VERSION "All_Common"

NS_ :

BS_:

BU_: IPC PCM VSA ADAS UNKNOWN

BO_ 422 IPC_0x1A6: 8 IPC
 SG_ HEADLIGHT_STATE : 0|2@1+ (1,0) [0|3] ""  PCM
 SG_ LIGHTING_STATUS_TBD : 2|1@1+ (1,0) [0|1] ""  PCM
 SG_ BRAKE_FLUID_LEVEL : 3|1@1+ (1,0) [0|1] ""  PCM
 SG_ PARKBRAKE_CURRENT : 4|1@1+ (1,0) [0|1] ""  PCM
 SG_ CRUISE_CONTROL_SYSTEM_SWITCH_STATUS : 5|3@1+ (1,0) [0|7] ""  PCM
 SG_ UNKNOWN_1 : 8|2@1+ (1,0) [0|3] ""  PCM
 SG_ SELECTED_BODY_STATUS_0 : 10|1@1+ (1,0) [0|1] ""  PCM
 SG_ SELECTED_BODY_STATUS_1 : 11|1@1+ (1,0) [0|1] ""  PCM
 SG_ BODY_STATUS : 12|2@1+ (1,0) [0|3] ""  PCM
 SG_ UNKNOWN_2 : 14|2@1+ (1,0) [0|3] ""  PCM
 SG_ FCAN_30C_STATUS_6 : 16|1@1+ (1,0) [0|1] ""  PCM
 SG_ FCAN_30C_STATUS_7 : 17|1@1+ (1,0) [0|1] ""  PCM
 SG_ BACKUP_LIGHT_SWITCH_REF : 18|1@1+ (1,0) [0|1] ""  PCM
 SG_ STATUS_BIT_1 : 19|1@1+ (1,0) [0|1] ""  PCM
 SG_ AC_COMPRESSOR_ON : 20|1@1+ (1,0) [0|1] ""  PCM
 SG_ STATUS_BIT_2 : 21|1@1+ (1,0) [0|1] ""  PCM
 SG_ STATUS_BIT_1_TBD : 22|1@1+ (1,0) [0|1] ""  PCM
 SG_ MONITOR_STATUS : 23|1@1+ (1,0) [0|1] ""  PCM
 SG_ FUEL_LEVEL_SCALED : 24|8@1+ (1,0) [0|255] ""  PCM
 SG_ FUEL_LEVEL_SENSOR_VOLTAGE : 32|8@1+ (0.01953130029153824,0) [0|4.980481574342251] "V"  PCM
 SG_ STATUS_BIT_3 : 40|1@1+ (1,0) [0|1] ""  PCM
 SG_ STATUS_BIT_4 : 41|1@1+ (1,0) [0|1] ""  PCM
 SG_ ACC_LKAS_SWITCH_STATUS_REF : 42|3@1+ (1,0) [0|7] ""  PCM
 SG_ UNKNOWN_3 : 45|2@1+ (1,0) [0|3] ""  PCM
 SG_ CRUISE_MAIN_SWITCH_HIDS_IHCC_ACC_INDICATOR : 47|1@1+ (1,0) [0|1] ""  PCM
 SG_ UNKNOWN_4 : 48|5@1+ (1,0) [0|31] ""  PCM
 SG_ FCAN_1FA_RECEIVE_FAULT : 53|1@1+ (1,0) [0|1] ""  PCM
 SG_ FCAN_RECEIVE_FAULT_A : 54|1@1+ (1,0) [0|1] ""  PCM
 SG_ FCAN_RECEIVE_FAULT_B : 55|1@1+ (1,0) [0|1] ""  PCM
 SG_ CHECKSUM : 56|4@1+ (1,0) [0|15] ""  PCM
 SG_ COUNTER : 60|2@1+ (1,0) [0|3] ""  PCM
 SG_ BCAN_SUPERVISION : 62|1@1+ (1,0) [0|1] ""  PCM
 SG_ STATUS_BIT_2_TBD : 63|1@1+ (1,0) [0|1] ""  PCM
VAL_ 422 CRUISE_CONTROL_SYSTEM_SWITCH_STATUS 0 "DEFAULT" 1 "MAIN_SWITCH" 2 "CANCEL_SWITCH" 3 "SET_SWITCH" 4 "RESUME_SWITCH" 5 "UNKNOWN" 6 "SIGNAL_LOST" 7 "SIGNAL_SHORT" ;
VAL_ 422 BRAKE_FLUID_LEVEL 0 "ENOUGH" 1 "LOW" ;
VAL_ 422 HEADLIGHT_STATE 0 "OFF_OR_UNAVAILABLE" 1 "PARKING_LIGHTS" 2 "LOW_BEAM" 3 "HIGH_BEAM" ;
VAL_ 422 ACC_LKAS_SWITCH_STATUS_REF 0 "NO_SWITCH_REQUEST" 1 "LKAS_SWITCH" 3 "DISTANCE_SWITCH" 6 "SWITCH_CIRCUIT_OPEN" 7 "SWITCH_CIRCUIT_SHORT" ;

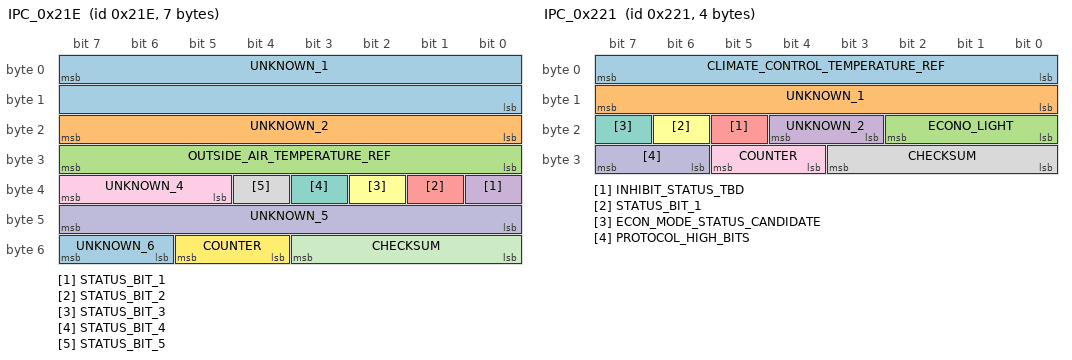
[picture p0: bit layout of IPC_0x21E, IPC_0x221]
BO_ 542 IPC_0x21E: 7 IPC
 SG_ UNKNOWN_1 : 7|16@0+ (1,0) [0|65535] ""  PCM
 SG_ UNKNOWN_2 : 16|8@1+ (1,0) [0|255] ""  PCM
 SG_ OUTSIDE_AIR_TEMPERATURE_REF : 24|8@1+ (10,-400) [-400|2150] "internal count"  PCM
 SG_ STATUS_BIT_1 : 32|1@1+ (1,0) [0|1] ""  PCM
 SG_ STATUS_BIT_2 : 33|1@1+ (1,0) [0|1] ""  PCM
 SG_ STATUS_BIT_3 : 34|1@1+ (1,0) [0|1] ""  PCM
 SG_ STATUS_BIT_4 : 35|1@1+ (1,0) [0|1] ""  PCM
 SG_ STATUS_BIT_5 : 36|1@1+ (1,0) [0|1] ""  PCM
 SG_ UNKNOWN_4 : 37|3@1+ (1,0) [0|7] ""  PCM
 SG_ UNKNOWN_5 : 40|8@1+ (1,0) [0|255] ""  PCM
 SG_ CHECKSUM : 48|4@1+ (1,0) [0|15] ""  PCM
 SG_ COUNTER : 52|2@1+ (1,0) [0|3] ""  PCM
 SG_ UNKNOWN_6 : 54|2@1+ (1,0) [0|3] ""  PCM
CM_ SG_ 542 OUTSIDE_AIR_TEMPERATURE_REF "Outside air temperature when supplied. Scaled to PCM internal counts.";

BO_ 545 IPC_0x221: 4 IPC
 SG_ CLIMATE_CONTROL_TEMPERATURE_REF : 0|8@1+ (1,-30) [-30|225] "degC"  PCM
 SG_ UNKNOWN_1 : 8|8@1+ (1,0) [0|255] ""  PCM
 SG_ ECONO_LIGHT : 16|3@1+ (1,0) [0|7] ""  PCM
 SG_ UNKNOWN_2 : 19|2@1+ (1,0) [0|3] ""  PCM
 SG_ INHIBIT_STATUS_TBD : 21|1@1+ (1,0) [0|1] ""  PCM
 SG_ STATUS_BIT_1 : 22|1@1+ (1,0) [0|1] ""  PCM
 SG_ ECON_MODE_STATUS_CANDIDATE : 23|1@1+ (1,0) [0|1] ""  PCM
 SG_ CHECKSUM : 24|4@1+ (1,0) [0|15] ""  PCM
 SG_ COUNTER : 28|2@1+ (1,0) [0|3] ""  PCM
 SG_ PROTOCOL_HIGH_BITS : 30|2@1+ (1,0) [0|3] ""  PCM
VAL_ 545 ECONO_LIGHT 0 "OFF" 3 "ON" ;
CM_ SG_ 545 CLIMATE_CONTROL_TEMPERATURE_REF "Can feed the PCM A/C temperature input.";

BO_ 660 IPC_0x294: 8 IPC
 SG_ STATUS_BIT_1 : 0|1@1+ (1,0) [0|1] ""  PCM
 SG_ VSA_UNAVAILABLE_STATUS : 1|1@1+ (1,0) [0|1] ""  PCM
 SG_ STATUS_BIT_2 : 2|1@1+ (1,0) [0|1] ""  PCM
 SG_ FRONT_WIPER_SWITCH_MODE_REF : 3|2@1+ (1,0) [0|3] ""  PCM
 SG_ BLINKER_LEFT : 5|1@1+ (1,0) [0|1] ""  PCM
 SG_ BLINKER_RIGHT : 6|1@1+ (1,0) [0|1] ""  PCM
 SG_ STATUS_BIT_3 : 7|1@1+ (1,0) [0|1] ""  PCM
 SG_ PANEL_BRIGHTNESS_LEVEL_CODE_REF : 8|6@1+ (1,0) [0|63] ""  PCM
 SG_ PRIMARY_PRESET_AT_MIN_REF : 14|1@1+ (1,0) [0|1] ""  PCM
 SG_ PRESET_STATUS : 15|1@1+ (1,0) [0|1] ""  PCM
 SG_ AUTO_LIGHT_SENSOR_DATA_UNAVAILABLE_REF : 16|1@1+ (1,0) [0|1] ""  PCM
 SG_ STATUS_BIT_4 : 17|1@1+ (1,0) [0|1] ""  PCM
 SG_ UNKNOWN_D2_BIT2 : 18|1@1+ (1,0) [0|1] ""  PCM
 SG_ FRONT_WIPER_SWITCH_CONFLICT_REF : 19|1@1+ (1,0) [0|1] ""  PCM
 SG_ MICU_BODY_STATUS_DATA_UNAVAILABLE_REF : 20|1@1+ (1,0) [0|1] ""  PCM
 SG_ LEFT_DOOR_STATUS_DATA_UNAVAILABLE_REF : 21|1@1+ (1,0) [0|1] ""  PCM
 SG_ CLIMATE_CONTROL_DATA_UNAVAILABLE_REF : 22|1@1+ (1,0) [0|1] ""  PCM
 SG_ LIGHTING_WIPER_DATA_UNAVAILABLE_REF : 23|1@1+ (1,0) [0|1] ""  PCM
 SG_ TOTAL_MILEAGE : 31|24@0+ (1,0) [0|16777215] "km"  PCM
 SG_ TRANSITION_LATCH_INPUT_TBD : 48|1@1+ (1,0) [0|1] ""  PCM
 SG_ UNKNOWN_2 : 49|7@1+ (1,0) [0|127] ""  PCM
 SG_ CHECKSUM : 56|4@1+ (1,0) [0|15] ""  PCM
 SG_ COUNTER : 60|2@1+ (1,0) [0|3] ""  PCM
 SG_ PROTOCOL_FLAGS : 62|2@1+ (1,0) [0|3] ""  PCM
VAL_ 660 FRONT_WIPER_SWITCH_MODE_REF 0 "OFF_OR_INVALID" 1 "INTERMITTENT_OR_AUTO" 2 "LOW" 3 "HIGH_OR_MIST" ;
CM_ SG_ 660 PRIMARY_PRESET_AT_MIN_REF "Primary brightness preset is at level 1";

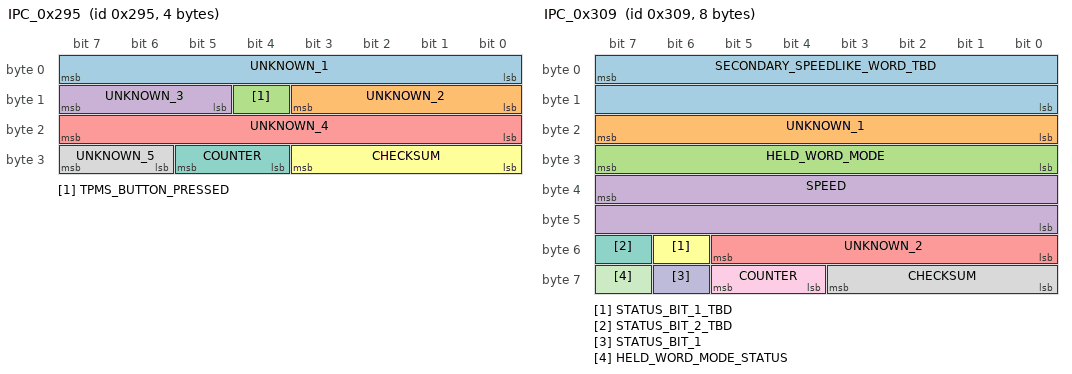
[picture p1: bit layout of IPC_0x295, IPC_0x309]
BO_ 661 IPC_0x295: 4 IPC
 SG_ UNKNOWN_1 : 0|8@1+ (1,0) [0|255] ""  UNKNOWN
 SG_ UNKNOWN_2 : 8|4@1+ (1,0) [0|15] ""  UNKNOWN
 SG_ TPMS_BUTTON_PRESSED : 12|1@1+ (1,0) [0|1] ""  UNKNOWN
 SG_ UNKNOWN_3 : 13|3@1+ (1,0) [0|7] ""  UNKNOWN
 SG_ UNKNOWN_4 : 16|8@1+ (1,0) [0|255] ""  UNKNOWN
 SG_ CHECKSUM : 24|4@1+ (1,0) [0|15] ""  UNKNOWN
 SG_ COUNTER : 28|2@1+ (1,0) [0|3] ""  UNKNOWN
 SG_ UNKNOWN_5 : 30|2@1+ (1,0) [0|3] ""  UNKNOWN

BO_ 777 IPC_0x309: 8 IPC
 SG_ SECONDARY_SPEEDLIKE_WORD_TBD : 7|16@0+ (1,0) [0|0] ""  PCM
 SG_ UNKNOWN_1 : 16|8@1+ (1,0) [0|255] ""  PCM
 SG_ HELD_WORD_MODE : 24|8@1+ (1,0) [0|255] ""  PCM
 SG_ SPEED : 39|16@0+ (0.01,0) [0|655.35] "km/h"  PCM
 SG_ UNKNOWN_2 : 48|6@1+ (1,0) [0|63] ""  PCM
 SG_ STATUS_BIT_1_TBD : 54|1@1+ (1,0) [0|1] ""  PCM
 SG_ STATUS_BIT_2_TBD : 55|1@1+ (1,0) [0|1] ""  PCM
 SG_ CHECKSUM : 56|4@1+ (1,0) [0|15] ""  PCM
 SG_ COUNTER : 60|2@1+ (1,0) [0|3] ""  PCM
 SG_ STATUS_BIT_1 : 62|1@1+ (1,0) [0|1] ""  PCM
 SG_ HELD_WORD_MODE_STATUS : 63|1@1+ (1,0) [0|1] ""  PCM

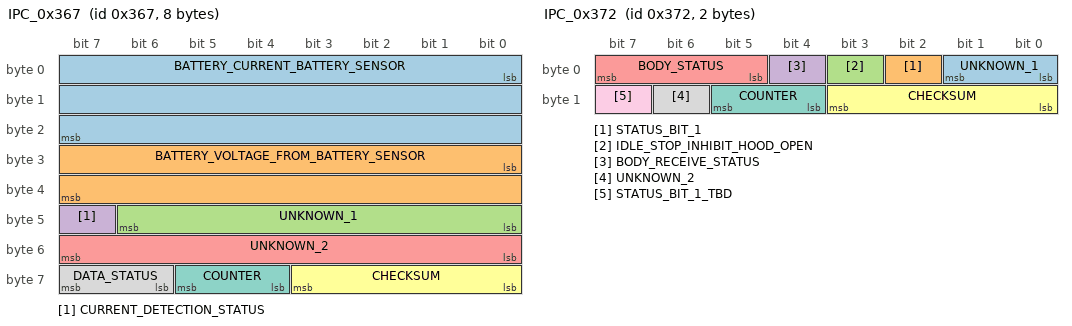
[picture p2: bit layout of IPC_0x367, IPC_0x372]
BO_ 871 IPC_0x367: 8 IPC
 SG_ BATTERY_CURRENT_BATTERY_SENSOR : 0|24@1+ (1,0) [0|16777215] "raw"  PCM
 SG_ BATTERY_VOLTAGE_FROM_BATTERY_SENSOR : 24|16@1+ (0.001,0) [0|65.535] "V"  PCM
 SG_ UNKNOWN_1 : 40|7@1+ (1,0) [0|127] ""  PCM
 SG_ CURRENT_DETECTION_STATUS : 47|1@1+ (1,0) [0|1] ""  PCM
 SG_ UNKNOWN_2 : 48|8@1+ (1,0) [0|255] ""  PCM
 SG_ CHECKSUM : 56|4@1+ (1,0) [0|15] ""  PCM
 SG_ COUNTER : 60|2@1+ (1,0) [0|3] ""  PCM
 SG_ DATA_STATUS : 62|2@1+ (1,0) [0|3] ""  PCM
VAL_ 871 CURRENT_DETECTION_STATUS 0 "NORMAL_CONDITION" 1 "CIRCUIT_OPEN_FAILURE" ;

VAL_ 871 DATA_STATUS 0 "NORMAL" 1 "INVALID_DATA" 2 "RECEIVE_TIMEOUT" ;
CM_ SG_ 871 CURRENT_DETECTION_STATUS "Also feeds Voltage Detection Status and Temperature Detection Status";

BO_ 882 IPC_0x372: 2 IPC
 SG_ UNKNOWN_1 : 0|2@1+ (1,0) [0|3] ""  PCM
 SG_ STATUS_BIT_1 : 2|1@1+ (1,0) [0|1] ""  PCM
 SG_ IDLE_STOP_INHIBIT_HOOD_OPEN : 3|1@1+ (1,0) [0|1] ""  PCM
 SG_ BODY_RECEIVE_STATUS : 4|1@1+ (1,0) [0|1] ""  PCM
 SG_ BODY_STATUS : 5|3@1+ (1,0) [0|7] ""  PCM
 SG_ CHECKSUM : 8|4@1+ (1,0) [0|15] ""  PCM
 SG_ COUNTER : 12|2@1+ (1,0) [0|3] ""  PCM
 SG_ UNKNOWN_2 : 14|1@1+ (1,0) [0|0] ""  PCM
 SG_ STATUS_BIT_1_TBD : 15|1@1+ (1,0) [0|0] ""  PCM
VAL_ 882 IDLE_STOP_INHIBIT_HOOD_OPEN 0 "NORMAL" 1 "INHIBITED" ;

BO_ 884 IPC_0x374: 8 IPC
 SG_ OUTSIDE_AIR_TEMPERATURE : 0|8@1+ (1,-40) [-39|62] "degC"  VSA
 SG_ UNKNOWN_D1_LOW_NIBBLE : 8|4@1+ (1,0) [0|15] ""  UNKNOWN
 SG_ RAIN_SENSOR_INT_WIPE_STATE_REF : 12|1@1+ (1,0) [0|1] ""  UNKNOWN
 SG_ AL_PARKING_LIGHT_COMMAND : 13|1@1+ (1,0) [0|1] ""  UNKNOWN
 SG_ AL_SENSOR_HEAD_LIGHT_COMMAND : 14|1@1+ (1,0) [0|1] ""  UNKNOWN
 SG_ REAR_FOG_INDICATOR_REQUEST_REF : 15|1@1+ (1,0) [0|1] ""  UNKNOWN
 SG_ FRONT_FOG_LIGHT_COMMAND_REF : 16|1@1+ (1,0) [0|1] ""  UNKNOWN
 SG_ UNKNOWN_D2_BITS1_TO_6 : 17|6@1+ (1,0) [0|63] ""  UNKNOWN
 SG_ LKAS_AMBER_IND_FEEDBACK_REF : 23|1@1+ (1,0) [0|1] ""  ADAS
 SG_ AUTO_LIGHT_SENSOR_RAW : 24|8@1+ (1,0) [0|255] ""  UNKNOWN
 SG_ DISPLAY_NOTICE_CODE_REF : 32|8@1+ (1,0) [0|255] ""  UNKNOWN
 SG_ PARKING_BRAKE_CHIME_STATUS_REF : 40|1@1+ (1,0) [0|1] ""  UNKNOWN
 SG_ DRIVER_SEAT_BELT_CHIME_ACTIVE : 41|1@1+ (1,0) [0|1] ""  UNKNOWN
 SG_ PASS_SEAT_BELT_CHIME_ACTIVE_REF : 42|1@1+ (1,0) [0|1] ""  UNKNOWN
 SG_ UNKNOWN_D5_BITS3_TO_4 : 43|2@1+ (1,0) [0|3] ""  UNKNOWN
 SG_ HIGH_BEAM_FLASH_SWITCH_REF : 45|1@1+ (1,0) [0|1] ""  UNKNOWN
 SG_ HEADLIGHT_SWITCH_AUTO_REF : 46|1@1+ (1,0) [0|1] ""  UNKNOWN
 SG_ HIGH_BEAM_HOLD_SWITCH_REF : 47|1@1+ (1,0) [0|1] ""  UNKNOWN
 SG_ RAIN_SENSOR_HIGH_WIPE_REQ_REF : 48|1@1+ (1,0) [0|1] ""  ADAS
 SG_ RAIN_SENSOR_LOW_WIPE_REQ_REF : 49|1@1+ (1,0) [0|1] ""  ADAS
 SG_ RAIN_SENSOR_SINGLE_WIPE_REQ_REF : 50|1@1+ (1,0) [0|1] ""  ADAS
 SG_ FRONT_WIPER_SWITCH_CONFLICT_REF : 51|1@1+ (1,0) [0|1] ""  ADAS
 SG_ FRONT_WIPER_SWITCH : 52|2@1+ (1,0) [0|3] ""  ADAS
 SG_ HEADLIGHT_DEMAND_STATE_REF : 54|2@1+ (1,0) [0|3] ""  UNKNOWN
 SG_ CHECKSUM : 56|4@1+ (1,0) [0|15] ""  VSA,ADAS
 SG_ COUNTER : 60|2@1+ (1,0) [0|3] ""  VSA,ADAS
 SG_ UNKNOWN_D7_HIGH_BITS : 62|2@1+ (1,0) [0|3] ""  UNKNOWN
VAL_ 884 OUTSIDE_AIR_TEMPERATURE 0 "UNAVAILABLE" 255 "INVALID" ;
VAL_ 884 DISPLAY_NOTICE_CODE_REF 0 "NO_ASSOCIATED_CODE_REF" 13 "12V_BATTERY_CHARGING_PROBLEM_REF" 15 "EMISSIONS_SYSTEM_PROBLEM_REF" 31 "ENGINE_COOLING_PROBLEM_REF" 199 "KEYLESS_START_SYSTEM_PROBLEM_REF" 201 "BRAKE_PUSH_START_PROMPT_REF" 205 "VSA_PROBLEM_REF" 239 "REPLACE_12V_BATTERY_REF" 241 "CHARGING_SYSTEM_PROBLEM_REF" 243 "HILL_START_ASSIST_PROBLEM_REF" 51 "ACC_PROBLEM_REF" 55 "CMBS_PROBLEM_REF" 75 "KEYLESS_REMOTE_NOT_DETECTED_REF" 79 "FASTEN_SEAT_BELT_REF" 111 "LKAS_PROBLEM_REF" 131 "BRAKE_SYSTEM_PROBLEM_REF" 249 "TO_SHIFT_DEPRESS_BRAKE_PEDAL_REF" 252 "CHECK_SYSTEM_APPLY_PARKING_BRAKE_WHEN_PARKED_REF" 185 "FORWARD_COLLISION_WARNING_REF" 187 "LKAS_STEERING_REQUIRED_REF" 189 "LANE_DEPARTURE_STEERING_PROMPT_REF" 191 "LKAS_OFF_CAMERA_OVERHEAT_REF" 224 "TO_START_ENGINE_BRAKE_OR_CLUTCH_REF" 232 "DEPRESS_BRAKE_HARDER_OR_CLUTCH_FULLY_REF" 250 "TO_SHIFT_RELEASE_ACCELERATOR_PEDAL_REF" 1 "BRAKE_FLUID_LOW_REF" 3 "RELEASE_PARKING_BRAKE_REF" 19 "SRS_SYSTEM_PROBLEM_REF" 21 "ABS_SYSTEM_PROBLEM_REF" 37 "WASHER_FLUID_LOW_REF" 47 "POWER_STEERING_SYSTEM_PROBLEM_REF" 73 "KEYLESS_ACCESS_SYSTEM_PROBLEM_REF" 77 "KEYLESS_REMOTE_BATTERY_LOW_REF" 87 "DOOR_AJAR_REF" 93 "TAILGATE_AJAR_REF" 95 "DOOR_AND_TAILGATE_AJAR_REF" 109 "ENGINE_TEMPERATURE_HIGH_REF" 161 "PARKING_SENSOR_PROXIMITY_REF" 163 "PARKING_SENSOR_SYSTEM_PROBLEM_REF" 209 "CHECK_TIRE_PRESSURE_REF" 221 "TRANSMISSION_TEMPERATURE_HIGH_REF" 222 "HOOD_OPEN_REF" 234 "HIGH_BEAM_SUPPORT_SYSTEM_PROBLEM_REF" 251 "DOOR_OPEN_SHIFT_TO_PARK_REF" ;
VAL_ 884 FRONT_WIPER_SWITCH 0 "PARKED_REF" 1 "INTERMITTENT_OR_AUTO" 2 "LOW_REF" 3 "HIGH_OR_MIST_REF" ;
VAL_ 884 HEADLIGHT_DEMAND_STATE_REF 0 "NO_DEMAND_OR_DEFAULT_REF" 1 "HEADLIGHT_DEMAND_REF" 3 "SWITCH_CONFLICT_REF" ;
CM_ SG_ 884 AL_PARKING_LIGHT_COMMAND "Commands the automatic parking lights";
CM_ SG_ 884 AL_SENSOR_HEAD_LIGHT_COMMAND "Commands the automatic headlights";
CM_ SG_ 884 AUTO_LIGHT_SENSOR_RAW "Raw automatic light sensor reading";

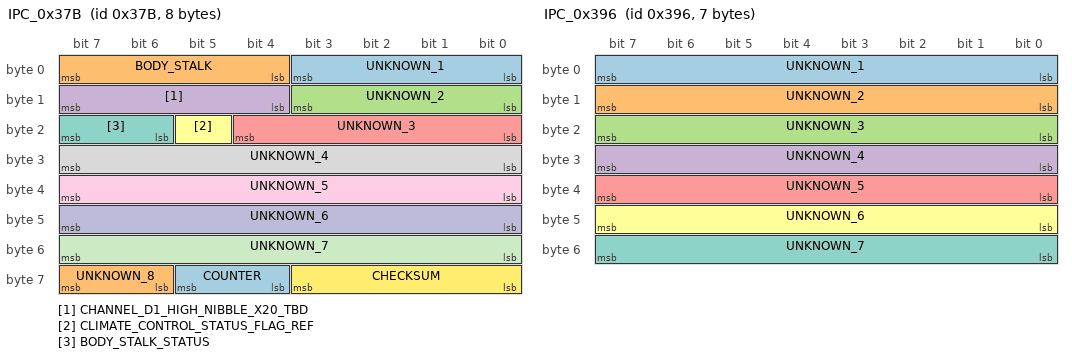
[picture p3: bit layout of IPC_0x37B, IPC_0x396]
BO_ 891 IPC_0x37B: 8 IPC
 SG_ UNKNOWN_1 : 0|4@1+ (1,0) [0|15] ""  PCM
 SG_ BODY_STALK : 4|4@1+ (1,0) [0|15] ""  PCM
 SG_ UNKNOWN_2 : 8|4@1+ (1,0) [0|15] ""  PCM
 SG_ CHANNEL_D1_HIGH_NIBBLE_X20_TBD : 12|4@1+ (1,0) [0|15] ""  PCM
 SG_ UNKNOWN_3 : 16|5@1+ (1,0) [0|31] ""  PCM
 SG_ CLIMATE_CONTROL_STATUS_FLAG_REF : 21|1@1+ (1,0) [0|1] ""  PCM
 SG_ BODY_STALK_STATUS : 22|2@1+ (1,0) [0|3] ""  PCM
 SG_ UNKNOWN_4 : 24|8@1+ (1,0) [0|255] ""  PCM
 SG_ UNKNOWN_5 : 32|8@1+ (1,0) [0|255] ""  PCM
 SG_ UNKNOWN_6 : 40|8@1+ (1,0) [0|255] ""  PCM
 SG_ UNKNOWN_7 : 48|8@1+ (1,0) [0|255] ""  PCM
 SG_ CHECKSUM : 56|4@1+ (1,0) [0|15] ""  PCM
 SG_ COUNTER : 60|2@1+ (1,0) [0|3] ""  PCM
 SG_ UNKNOWN_8 : 62|2@1+ (1,0) [0|3] ""  PCM
CM_ SG_ 891 CLIMATE_CONTROL_STATUS_FLAG_REF "Exact climate-control function is unknown.";

BO_ 918 IPC_0x396: 7 IPC
 SG_ UNKNOWN_1 : 0|8@1+ (1,0) [0|255] ""  UNKNOWN
 SG_ UNKNOWN_2 : 8|8@1+ (1,0) [0|255] ""  UNKNOWN
 SG_ UNKNOWN_3 : 16|8@1+ (1,0) [0|255] ""  UNKNOWN
 SG_ UNKNOWN_4 : 24|8@1+ (1,0) [0|255] ""  UNKNOWN
 SG_ UNKNOWN_5 : 32|8@1+ (1,0) [0|255] ""  UNKNOWN
 SG_ UNKNOWN_6 : 40|8@1+ (1,0) [0|255] ""  UNKNOWN
 SG_ UNKNOWN_7 : 48|8@1+ (1,0) [0|255] ""  UNKNOWN

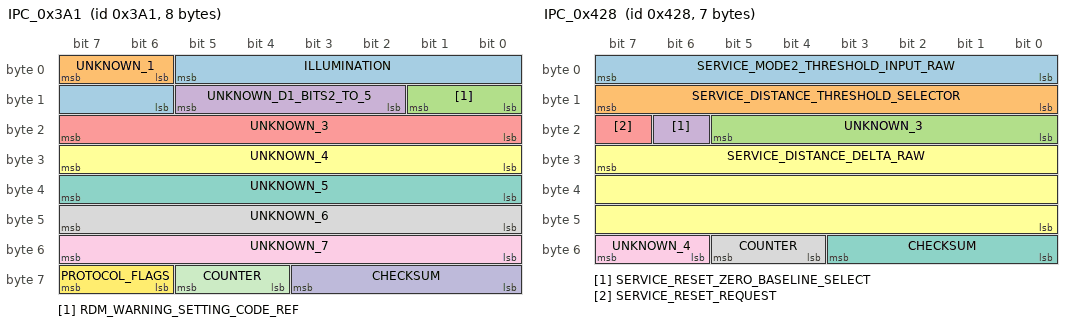
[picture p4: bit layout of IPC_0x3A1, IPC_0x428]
BO_ 929 IPC_0x3A1: 8 IPC
 SG_ ILLUMINATION : 5|8@0+ (1,0) [0|255] ""  UNKNOWN
 SG_ UNKNOWN_1 : 6|2@1+ (1,0) [0|3] ""  UNKNOWN
 SG_ RDM_WARNING_SETTING_CODE_REF : 8|2@1+ (1,0) [0|3] ""  UNKNOWN
 SG_ UNKNOWN_D1_BITS2_TO_5 : 10|4@1+ (1,0) [0|15] ""  UNKNOWN
 SG_ UNKNOWN_3 : 16|8@1+ (1,0) [0|255] ""  UNKNOWN
 SG_ UNKNOWN_4 : 24|8@1+ (1,0) [0|255] ""  UNKNOWN
 SG_ UNKNOWN_5 : 32|8@1+ (1,0) [0|255] ""  UNKNOWN
 SG_ UNKNOWN_6 : 40|8@1+ (1,0) [0|255] ""  UNKNOWN
 SG_ UNKNOWN_7 : 48|8@1+ (1,0) [0|255] ""  UNKNOWN
 SG_ CHECKSUM : 56|4@1+ (1,0) [0|15] ""  UNKNOWN
 SG_ COUNTER : 60|2@1+ (1,0) [0|3] ""  UNKNOWN
 SG_ PROTOCOL_FLAGS : 62|2@1+ (1,0) [0|3] ""  UNKNOWN
VAL_ 929 RDM_WARNING_SETTING_CODE_REF 2 "WARNING_ONLY" ;

BO_ 1029 IPC_0x405: 8 IPC
 SG_ MIL_DERIVED_STATUS : 0|1@1+ (1,0) [0|1] ""  UNKNOWN
 SG_ UNKNOWN_D0_BIT1 : 1|1@1+ (1,0) [0|1] ""  UNKNOWN
 SG_ LOW_FUEL_WARNING_REF : 2|1@1+ (1,0) [0|1] ""  UNKNOWN
 SG_ UNKNOWN_D0_BITS3_TO_7 : 3|5@1+ (1,0) [0|31] ""  UNKNOWN
 SG_ ABS_WARNING_REF : 8|1@1+ (1,0) [0|1] ""  UNKNOWN
 SG_ ANY_ALERT_ACTIVE : 9|1@1+ (1,0) [0|1] ""  UNKNOWN
 SG_ VSA_PRIORITY_WARNING_REQUEST_REF : 10|1@1+ (1,0) [0|1] ""  UNKNOWN
 SG_ VSA_DISABLED_STATUS : 11|1@1+ (1,0) [0|1] ""  UNKNOWN
 SG_ UNKNOWN_2 : 12|2@1+ (1,0) [0|0] ""  UNKNOWN
 SG_ STATUS_BIT_1_TBD : 14|1@1+ (1,0) [0|0] ""  UNKNOWN
 SG_ STATUS_BIT_2_TBD : 15|1@1+ (1,0) [0|0] ""  UNKNOWN
 SG_ STATUS_BIT_3_TBD : 16|1@1+ (1,0) [0|0] ""  UNKNOWN
 SG_ STATUS_BIT_4_TBD : 17|1@1+ (1,0) [0|0] ""  UNKNOWN
 SG_ STATUS_BIT_1 : 18|1@1+ (1,0) [0|0] ""  UNKNOWN
 SG_ BRAKE_FLUID_LEVEL : 19|1@1+ (1,0) [0|1] ""  UNKNOWN
 SG_ BRAKE_SYSTEM_WARNING_REF : 20|1@1+ (1,0) [0|1] ""  UNKNOWN
 SG_ UNKNOWN_3 : 21|2@1+ (1,0) [0|3] ""  UNKNOWN
 SG_ LOW_OIL_PRESSURE_WARNING_REF : 23|1@1+ (1,0) [0|1] ""  UNKNOWN
 SG_ CHARGING_SYSTEM_WARNING_REF : 24|1@1+ (1,0) [0|1] ""  UNKNOWN
 SG_ SRS_STATUS : 25|1@1+ (1,0) [0|1] ""  UNKNOWN
 SG_ UNKNOWN_4 : 26|6@1+ (1,0) [0|63] ""  UNKNOWN
 SG_ UNKNOWN_5 : 32|5@1+ (1,0) [0|31] ""  UNKNOWN
 SG_ DOOR_OPEN_FL : 37|1@1+ (1,0) [0|1] ""  UNKNOWN
 SG_ DOOR_OPEN_FR : 38|1@1+ (1,0) [0|1] ""  UNKNOWN
 SG_ DOOR_OPEN_RL : 39|1@1+ (1,0) [0|1] ""  UNKNOWN
 SG_ DOOR_OPEN_RR : 40|1@1+ (1,0) [0|1] ""  UNKNOWN
 SG_ TRUNK_OPEN : 41|1@1+ (1,0) [0|1] ""  UNKNOWN
 SG_ IMMOBILIZER_LAMP_STATE_TBD : 42|1@1+ (1,0) [0|0] ""  UNKNOWN
 SG_ UNKNOWN_6 : 43|5@1+ (1,0) [0|0] ""  UNKNOWN
 SG_ UNKNOWN_7 : 48|8@1+ (1,0) [0|255] ""  UNKNOWN
 SG_ CHECKSUM : 56|4@1+ (1,0) [0|15] ""  UNKNOWN
 SG_ COUNTER : 60|2@1+ (1,0) [0|3] ""  UNKNOWN
 SG_ PROTOCOL_FLAGS : 62|2@1+ (1,0) [0|3] ""  UNKNOWN
VAL_ 1029 BRAKE_FLUID_LEVEL 0 "ENOUGH" 1 "LOW" ;

BO_ 1064 IPC_0x428: 7 IPC
 SG_ SERVICE_MODE2_THRESHOLD_INPUT_RAW : 0|8@1+ (1,0) [0|255] ""  PCM
 SG_ SERVICE_DISTANCE_THRESHOLD_SELECTOR : 8|8@1+ (1,0) [0|255] ""  PCM
 SG_ UNKNOWN_3 : 16|6@1+ (1,0) [0|63] ""  PCM
 SG_ SERVICE_RESET_ZERO_BASELINE_SELECT : 22|1@1+ (1,0) [0|1] ""  PCM
 SG_ SERVICE_RESET_REQUEST : 23|1@1+ (1,0) [0|1] ""  PCM
 SG_ SERVICE_DISTANCE_DELTA_RAW : 31|24@0+ (1,0) [0|16777215] ""  PCM
 SG_ CHECKSUM : 48|4@1+ (1,0) [0|15] ""  PCM
 SG_ COUNTER : 52|2@1+ (1,0) [0|3] ""  PCM
 SG_ UNKNOWN_4 : 54|2@1+ (1,0) [0|3] ""  PCM
CM_ SG_ 1064 SERVICE_DISTANCE_DELTA_RAW "Distance accumulated from the service baseline.";

BO_ 1088 IPC_0x440: 8 IPC
 SG_ MUX M : 0|8@1+ (1,0) [0|255] ""  PCM
 SG_ UNKNOWN_1 m49 : 8|8@1+ (1,0) [0|255] ""  PCM
 SG_ P32_ESTIMATED_BATTERY_RESISTANCE_BATTERY_SENSOR m50 : 8|16@1+ (1,0) [0|65535] "raw"  PCM
 SG_ P33_IGNITION_OFF_CURRENT_HISTORY_BYTE_0 m51 : 8|8@1+ (1,0) [0|255] ""  PCM
 SG_ P39_IGNITION_OFF_DURATION_LOW_BYTE m57 : 8|8@1+ (1,0) [0|255] ""  PCM
 SG_ P3A_BATTERY_TEMPERATURE_CHECK_INPUT m58 : 8|8@1+ (1,-40) [-40|215] "degC"  PCM
 SG_ UNKNOWN_5 m0 : 8|8@1+ (1,0) [0|255] ""  PCM
 SG_ UNKNOWN_6 m49 : 16|8@1+ (1,0) [0|255] ""  PCM
 SG_ P33_IGNITION_OFF_CURRENT_HISTORY_BYTE_1 m51 : 16|8@1+ (1,0) [0|255] ""  PCM
 SG_ P39_IGNITION_OFF_DURATION_HIGH_BYTE_RAW m57 : 16|8@1+ (1,0) [0|255] ""  PCM
 SG_ UNKNOWN_9 m58 : 16|8@1+ (1,0) [0|255] ""  PCM
 SG_ UNKNOWN_10 m0 : 16|8@1+ (1,0) [0|255] ""  PCM
 SG_ P31_ESTIMATED_BATTERY_TEMPERATURE m49 : 24|8@1+ (1,-40) [-40|215] "degC"  PCM
 SG_ P32_BATTERY_CHARGE_COUNTER m50 : 24|16@1+ (3.5172,0) [0|230499.702] "A*s"  PCM
 SG_ P33_IGNITION_OFF_CURRENT_HISTORY_BYTE_2 m51 : 24|8@1+ (1,0) [0|255] ""  PCM
 SG_ P39_ESTIMATED_BATTERY_QUIESCENT_OR_OPEN_CIRCUIT_VOLTAGE m57 : 24|8@1+ (4,4600) [4600|5620] "code"  PCM
 SG_ UNKNOWN_13 m58 : 24|16@1+ (1,0) [0|65535] ""  PCM
 SG_ UNKNOWN_14 m0 : 24|8@1+ (1,0) [0|255] ""  PCM
 SG_ P31_SURVEY_INFOMATION_BATTERY_MANAGEMENT_1 m49 : 32|8@1+ (1,0) [0|255] "raw"  PCM
 SG_ P33_IGNITION_OFF_CURRENT_HISTORY_BYTE_3 m51 : 32|8@1+ (1,0) [0|255] ""  PCM
 SG_ P39_ESTIMATED_BATTERY_ABILITY_TO_DELIVER_CURRENT_VOLTAGE_SOH m57 : 32|8@1+ (1,0) [0|255] "raw"  PCM
 SG_ UNKNOWN_16 m0 : 32|8@1+ (1,0) [0|255] ""  PCM
 SG_ P31_BATTERY_MANAGEMENT_MODE m49 : 40|3@1+ (1,0) [0|7] ""  PCM
 SG_ P32_BATTERY_DISCHARGE_COUNTER m50 : 40|16@1+ (3.5172,0) [0|230499.702] "A*s"  PCM
 SG_ P33_IGNITION_OFF_CURRENT_HISTORY_BYTE_4 m51 : 40|8@1+ (1,0) [0|255] ""  PCM
 SG_ P39_ESTIMATED_BATTERY_VOLTAGE_AT_THE_SPECIFIED_HIGH_LOAD m57 : 40|8@1+ (25,0) [0|6375] "code"  PCM
 SG_ P3A_BATTERY_RESISTANCE_ADAPTATION_INPUT_REF m58 : 40|16@1+ (1,0) [0|65535] ""  PCM
 SG_ UNKNOWN_21 m0 : 40|8@1+ (1,0) [0|255] ""  PCM
 SG_ P31_BATTERY_RESISTANCE_ADAPTATION_CHANGE_CODE m49 : 43|2@1+ (1,0) [0|3] ""  PCM
 SG_ STATUS_BIT_1 m49 : 45|1@1+ (1,0) [0|1] ""  PCM
 SG_ STATUS_BIT_2 m49 : 46|1@1+ (1,0) [0|1] ""  PCM
 SG_ STATUS_BIT_3 m49 : 47|1@1+ (1,0) [0|1] ""  PCM
 SG_ UNKNOWN_23 m49 : 48|3@1+ (1,0) [0|7] ""  PCM
 SG_ UNKNOWN_24 m51 : 48|8@1+ (1,0) [0|255] ""  PCM
 SG_ P39_RESET_ON_BATTERY_SENSOR m57 : 48|1@1+ (1,0) [0|1] ""  PCM
 SG_ UNKNOWN_25 m0 : 48|8@1+ (1,0) [0|255] ""  PCM
 SG_ P39_SURVEY_INFOMATION_BATTERY_MANAGEMENT_3 m57 : 49|1@1+ (1,0) [0|1] ""  PCM
 SG_ STATUS_BIT_4 m57 : 50|1@1+ (1,0) [0|1] ""  PCM
 SG_ UNKNOWN_26 m49 : 51|3@1+ (1,0) [0|7] ""  PCM
 SG_ STATUS_BIT_5 m57 : 51|1@1+ (1,0) [0|1] ""  PCM
 SG_ UNKNOWN_27 m57 : 52|3@1+ (1,0) [0|7] ""  PCM
 SG_ STATUS_BIT_6 m49 : 54|1@1+ (1,0) [0|1] ""  PCM
 SG_ STATUS_BIT_7 m49 : 55|1@1+ (1,0) [0|1] ""  PCM
 SG_ STATUS_BIT_8 m57 : 55|1@1+ (1,0) [0|1] ""  PCM
 SG_ CHECKSUM : 56|4@1+ (1,0) [0|15] ""  PCM
 SG_ COUNTER : 60|2@1+ (1,0) [0|3] ""  PCM
 SG_ PAGE_STATUS : 62|2@1+ (1,0) [0|3] ""  PCM
SG_MUL_VAL_ 1088 UNKNOWN_1 MUX 49-49;
SG_MUL_VAL_ 1088 P32_ESTIMATED_BATTERY_RESISTANCE_BATTERY_SENSOR MUX 50-50;
SG_MUL_VAL_ 1088 P33_IGNITION_OFF_CURRENT_HISTORY_BYTE_0 MUX 51-51;
SG_MUL_VAL_ 1088 P39_IGNITION_OFF_DURATION_LOW_BYTE MUX 57-57;
SG_MUL_VAL_ 1088 P3A_BATTERY_TEMPERATURE_CHECK_INPUT MUX 58-58;
SG_MUL_VAL_ 1088 UNKNOWN_5 MUX 0-48, 52-56, 59-255;
SG_MUL_VAL_ 1088 UNKNOWN_6 MUX 49-49;
SG_MUL_VAL_ 1088 P33_IGNITION_OFF_CURRENT_HISTORY_BYTE_1 MUX 51-51;
SG_MUL_VAL_ 1088 P39_IGNITION_OFF_DURATION_HIGH_BYTE_RAW MUX 57-57;
SG_MUL_VAL_ 1088 UNKNOWN_9 MUX 58-58;
SG_MUL_VAL_ 1088 UNKNOWN_10 MUX 0-48, 52-56, 59-255;
SG_MUL_VAL_ 1088 P31_ESTIMATED_BATTERY_TEMPERATURE MUX 49-49;
SG_MUL_VAL_ 1088 P32_BATTERY_CHARGE_COUNTER MUX 50-50;
SG_MUL_VAL_ 1088 P33_IGNITION_OFF_CURRENT_HISTORY_BYTE_2 MUX 51-51;
SG_MUL_VAL_ 1088 P39_ESTIMATED_BATTERY_QUIESCENT_OR_OPEN_CIRCUIT_VOLTAGE MUX 57-57;
SG_MUL_VAL_ 1088 UNKNOWN_13 MUX 58-58;
SG_MUL_VAL_ 1088 UNKNOWN_14 MUX 0-48, 52-56, 59-255;
SG_MUL_VAL_ 1088 P31_SURVEY_INFOMATION_BATTERY_MANAGEMENT_1 MUX 49-49;
SG_MUL_VAL_ 1088 P33_IGNITION_OFF_CURRENT_HISTORY_BYTE_3 MUX 51-51;
SG_MUL_VAL_ 1088 P39_ESTIMATED_BATTERY_ABILITY_TO_DELIVER_CURRENT_VOLTAGE_SOH MUX 57-57;
SG_MUL_VAL_ 1088 UNKNOWN_16 MUX 0-48, 52-56, 59-255;
SG_MUL_VAL_ 1088 P31_BATTERY_MANAGEMENT_MODE MUX 49-49;
SG_MUL_VAL_ 1088 P32_BATTERY_DISCHARGE_COUNTER MUX 50-50;
SG_MUL_VAL_ 1088 P33_IGNITION_OFF_CURRENT_HISTORY_BYTE_4 MUX 51-51;
SG_MUL_VAL_ 1088 P39_ESTIMATED_BATTERY_VOLTAGE_AT_THE_SPECIFIED_HIGH_LOAD MUX 57-57;
SG_MUL_VAL_ 1088 P3A_BATTERY_RESISTANCE_ADAPTATION_INPUT_REF MUX 58-58;
SG_MUL_VAL_ 1088 UNKNOWN_21 MUX 0-48, 52-56, 59-255;
SG_MUL_VAL_ 1088 P31_BATTERY_RESISTANCE_ADAPTATION_CHANGE_CODE MUX 49-49;
SG_MUL_VAL_ 1088 STATUS_BIT_1 MUX 49-49;
SG_MUL_VAL_ 1088 STATUS_BIT_2 MUX 49-49;
SG_MUL_VAL_ 1088 STATUS_BIT_3 MUX 49-49;
SG_MUL_VAL_ 1088 UNKNOWN_23 MUX 49-49;
SG_MUL_VAL_ 1088 UNKNOWN_24 MUX 51-51;
SG_MUL_VAL_ 1088 P39_RESET_ON_BATTERY_SENSOR MUX 57-57;
SG_MUL_VAL_ 1088 UNKNOWN_25 MUX 0-48, 52-56, 59-255;
SG_MUL_VAL_ 1088 P39_SURVEY_INFOMATION_BATTERY_MANAGEMENT_3 MUX 57-57;
SG_MUL_VAL_ 1088 STATUS_BIT_4 MUX 57-57;
SG_MUL_VAL_ 1088 UNKNOWN_26 MUX 49-49;
SG_MUL_VAL_ 1088 STATUS_BIT_5 MUX 57-57;
SG_MUL_VAL_ 1088 UNKNOWN_27 MUX 57-57;
SG_MUL_VAL_ 1088 STATUS_BIT_6 MUX 49-49;
SG_MUL_VAL_ 1088 STATUS_BIT_7 MUX 49-49;
SG_MUL_VAL_ 1088 STATUS_BIT_8 MUX 57-57;
VAL_ 1088 PAGE_STATUS 0 "NORMAL" 1 "INVALID_DATA" 2 "RECEIVE_TIMEOUT" ;
CM_ SG_ 1088 P3A_BATTERY_TEMPERATURE_CHECK_INPUT "Raw 255 is ignored by the thermal comparison.";
CM_ SG_ 1088 P39_IGNITION_OFF_DURATION_HIGH_BYTE_RAW "Low six bits supply the upper duration bits";
CM_ SG_ 1088 UNKNOWN_23 "Status from LIN 0x31";

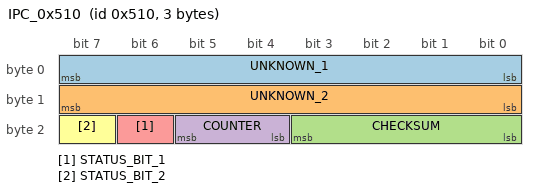
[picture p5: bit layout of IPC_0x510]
BO_ 1296 IPC_0x510: 3 IPC
 SG_ UNKNOWN_1 : 0|8@1+ (1,0) [0|255] ""  PCM
 SG_ UNKNOWN_2 : 8|8@1+ (1,0) [0|255] ""  PCM
 SG_ CHECKSUM : 16|4@1+ (1,0) [0|15] ""  PCM
 SG_ COUNTER : 20|2@1+ (1,0) [0|3] ""  PCM
 SG_ STATUS_BIT_1 : 22|1@1+ (1,0) [0|1] ""  PCM
 SG_ STATUS_BIT_2 : 23|1@1+ (1,0) [0|1] ""  PCM
